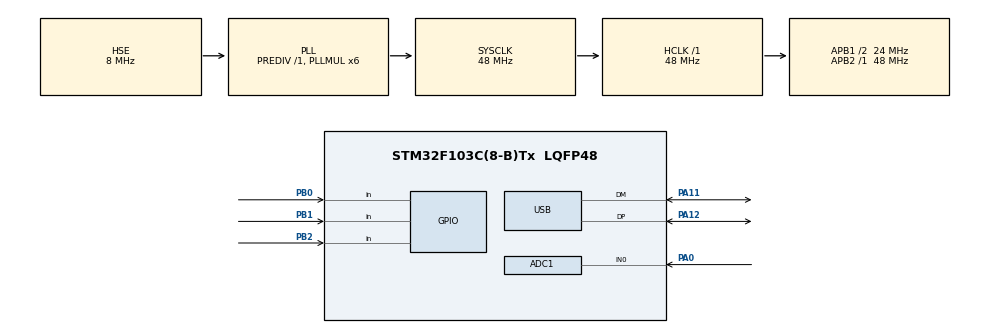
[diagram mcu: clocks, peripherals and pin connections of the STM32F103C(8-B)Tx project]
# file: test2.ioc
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ADC1.Channel-0\#ChannelRegularConversion=ADC_CHANNEL_0
ADC1.NbrOfConversionFlag=1
ADC1.Rank-0\#ChannelRegularConversion=1
ADC1.SamplingTime-0\#ChannelRegularConversion=ADC_SAMPLETIME_1CYCLE_5
ADC1.master=1
Mcu.Family=STM32F1
Mcu.Name=STM32F103C(8-B)Tx
Mcu.Package=LQFP48
NVIC.PriorityGroup=NVIC_PRIORITYGROUP_4
NVIC.USB_LP_CAN1_RX0_IRQn=true\:0\:0\:false\:false\:true\:false\:true\:true
PA0-WKUP.Signal=ADCx_IN0
PA11.Mode=Device
PA11.Signal=USB_DM
PA12.Mode=Device
PA12.Signal=USB_DP
PA13.Mode=Serial_Wire
PA13.Signal=SYS_JTMS-SWDIO
PA14.Mode=Serial_Wire
PA14.Signal=SYS_JTCK-SWCLK
PB0.Signal=GPIO_Input
PB1.Signal=GPIO_Input
PB2.Signal=GPIO_Input
PD0-OSC_IN.Mode=HSE-External-Oscillator
PD0-OSC_IN.Signal=RCC_OSC_IN
PD1-OSC_OUT.Mode=HSE-External-Oscillator
PD1-OSC_OUT.Signal=RCC_OSC_OUT
ProjectManager.HeapSize=0x200
ProjectManager.StackSize=0x400
ProjectManager.TargetToolchain=MDK-ARM V5.32
RCC.ADCPresc=RCC_ADCPCLK2_DIV4
RCC.AHBFreq_Value=48000000
RCC.APB1CLKDivider=RCC_HCLK_DIV2
RCC.APB1Freq_Value=24000000
RCC.APB1TimFreq_Value=48000000
RCC.APB2Freq_Value=48000000
RCC.APB2TimFreq_Value=48000000
RCC.HCLKFreq_Value=48000000
RCC.PLLMUL=RCC_PLL_MUL6
RCC.SYSCLKFreq_VALUE=48000000
RCC.SYSCLKSource=RCC_SYSCLKSOURCE_PLLCLK
RCC.USBFreq_Value=48000000
SH.ADCx_IN0.0=ADC1_IN0,IN0
USB_DEVICE.CLASS_NAME_FS=CDC
USB_DEVICE.VirtualMode=Cdc
USB_DEVICE.VirtualModeFS=Cdc_FS
VP_USB_DEVICE_VS_USB_DEVICE_CDC_FS.Mode=CDC_FS
board=custom

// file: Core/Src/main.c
/* USER CODE BEGIN Header */
/**
  ******************************************************************************
  * @file           : main.c
  * @brief          : Main program body
  ******************************************************************************
  * @attention
  *
  * Copyright (c) 2024 STMicroelectronics.
  * All rights reserved.
  *
  * This software is licensed under terms that can be found in the LICENSE file
  * in the root directory of this software component.
  * If no LICENSE file comes with this software, it is provided AS-IS.
  *
  ******************************************************************************
  */
/* USER CODE END Header */
#include "main.h"
#include "usb_device.h"
#include "usbd_cdc_if.h"
#include "stdbool.h"

ADC_HandleTypeDef hadc1;

void delay(uint32_t us){
	for(int i =0; i < us;i++) {
		__NOP;
	};
	}
void SystemClock_Config(void);
static void MX_GPIO_Init(void);
static void MX_ADC1_Init(void);

int main(void)
{

  /* MCU Configuration--------------------------------------------------------*/

  /* Reset of all peripherals, Initializes the Flash interface and the Systick. */
  HAL_Init();

  /* Configure the system clock */
  SystemClock_Config();

  /* Initialize all configured peripherals */
  MX_GPIO_Init();
  MX_ADC1_Init();
  MX_USB_DEVICE_Init();
	uint16_t adc_value = 0;
  char usb_tx_buffer[2];
  /* Infinite loop */
  /* USER CODE BEGIN WHILE */

	uint8_t buf[256];
	int count = 0;
  while (1)
  {
    /* USER CODE END WHILE */
		HAL_ADC_Start(&hadc1);
		HAL_ADC_PollForConversion(&hadc1, HAL_MAX_DELAY);
		adc_value = HAL_ADC_GetValue(&hadc1);
		uint8_t z = adc_value >>8 &0xFF;

		bool timediv = 0, voldiv = 0, hz = 0;

		if(HAL_GPIO_ReadPin(GPIOB, GPIO_PIN_0) == GPIO_PIN_RESET) {
			timediv = 1;
		}

		if(HAL_GPIO_ReadPin(GPIOB, GPIO_PIN_1) == GPIO_PIN_RESET) {
			voldiv = 1;
		}

		if(HAL_GPIO_ReadPin(GPIOB, GPIO_PIN_3) == GPIO_PIN_RESET) {
			hz = 1;
		}

		/**if(timediv) {
			z |= 1 << 7;
		} else {
			z &= ~(1<<7);
		}

		if(voldiv) {
			z |= 1<< 6;
		} else {
			z &= ~(1<<6);
		}

		if(hz) {
			z |= 1<<5;
		} else {
			z &= ~(1<<5);
		}
		**/

		buf[0 + 2 * count] = (adc_value &0xFF);
		buf[1 + 2 * count] = (z &0xFF);
 		count++;
		delay(1);
		if(count > 128) {
			CDC_Transmit_FS(buf,sizeof(buf));
			count = 0;
			delay(1000);
		}

  }
}

void SystemClock_Config(void)
{
  RCC_OscInitTypeDef RCC_OscInitStruct = {0};
  RCC_ClkInitTypeDef RCC_ClkInitStruct = {0};
  RCC_PeriphCLKInitTypeDef PeriphClkInit = {0};

  /** Initializes the RCC Oscillators according to the specified parameters
  * in the RCC_OscInitTypeDef structure.
  */
  RCC_OscInitStruct.OscillatorType = RCC_OSCILLATORTYPE_HSE;
  RCC_OscInitStruct.HSEState = RCC_HSE_ON;
  RCC_OscInitStruct.HSEPredivValue = RCC_HSE_PREDIV_DIV1;
  RCC_OscInitStruct.HSIState = RCC_HSI_ON;
  RCC_OscInitStruct.PLL.PLLState = RCC_PLL_ON;
  RCC_OscInitStruct.PLL.PLLSource = RCC_PLLSOURCE_HSE;
  RCC_OscInitStruct.PLL.PLLMUL = RCC_PLL_MUL6;
  if (HAL_RCC_OscConfig(&RCC_OscInitStruct) != HAL_OK)
  {
    Error_Handler();
  }

  /** Initializes the CPU, AHB and APB buses clocks
  */
  RCC_ClkInitStruct.ClockType = RCC_CLOCKTYPE_HCLK|RCC_CLOCKTYPE_SYSCLK
                              |RCC_CLOCKTYPE_PCLK1|RCC_CLOCKTYPE_PCLK2;
  RCC_ClkInitStruct.SYSCLKSource = RCC_SYSCLKSOURCE_PLLCLK;
  RCC_ClkInitStruct.AHBCLKDivider = RCC_SYSCLK_DIV1;
  RCC_ClkInitStruct.APB1CLKDivider = RCC_HCLK_DIV2;
  RCC_ClkInitStruct.APB2CLKDivider = RCC_HCLK_DIV1;

  if (HAL_RCC_ClockConfig(&RCC_ClkInitStruct, FLASH_LATENCY_1) != HAL_OK)
  {
    Error_Handler();
  }
  PeriphClkInit.PeriphClockSelection = RCC_PERIPHCLK_ADC|RCC_PERIPHCLK_USB;
  PeriphClkInit.AdcClockSelection = RCC_ADCPCLK2_DIV4;
  PeriphClkInit.UsbClockSelection = RCC_USBCLKSOURCE_PLL;
  if (HAL_RCCEx_PeriphCLKConfig(&PeriphClkInit) != HAL_OK)
  {
    Error_Handler();
  }
}

static void MX_ADC1_Init(void)
{

  ADC_ChannelConfTypeDef sConfig = {0};

  /** Common config
  */
  hadc1.Instance = ADC1;
  hadc1.Init.ScanConvMode = ADC_SCAN_DISABLE;
  hadc1.Init.ContinuousConvMode = DISABLE;
  hadc1.Init.DiscontinuousConvMode = DISABLE;
  hadc1.Init.ExternalTrigConv = ADC_SOFTWARE_START;
  hadc1.Init.DataAlign = ADC_DATAALIGN_RIGHT;
  hadc1.Init.NbrOfConversion = 1;
  if (HAL_ADC_Init(&hadc1) != HAL_OK)
  {
    Error_Handler();
  }

  /** Configure Regular Channel
  */
  sConfig.Channel = ADC_CHANNEL_1;
  sConfig.Rank = ADC_REGULAR_RANK_1;
  sConfig.SamplingTime = ADC_SAMPLETIME_1CYCLE_5;
  if (HAL_ADC_ConfigChannel(&hadc1, &sConfig) != HAL_OK)
  {
    Error_Handler();
  }

}

static void MX_GPIO_Init(void)
{
  GPIO_InitTypeDef GPIO_InitStruct = {0};

  /* GPIO Ports Clock Enable */
  __HAL_RCC_GPIOD_CLK_ENABLE();
  __HAL_RCC_GPIOA_CLK_ENABLE();
  __HAL_RCC_GPIOB_CLK_ENABLE();

  /*Configure GPIO pins : PB0 PB1 PB2 */
  GPIO_InitStruct.Pin = GPIO_PIN_0|GPIO_PIN_1|GPIO_PIN_3;
  GPIO_InitStruct.Mode = GPIO_MODE_INPUT;
  GPIO_InitStruct.Pull = GPIO_PULLUP;
  HAL_GPIO_Init(GPIOB, &GPIO_InitStruct);

}

void Error_Handler(void)
{
  __disable_irq();
  while (1)
  {
  }
}
